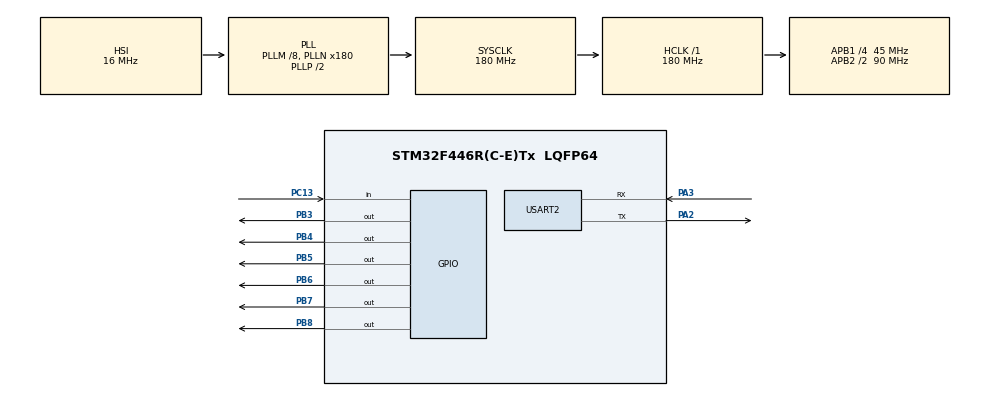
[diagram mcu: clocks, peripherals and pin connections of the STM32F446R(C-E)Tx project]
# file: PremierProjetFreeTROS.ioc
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FREERTOS.Tasks01=autoGreen,24,128,autoGreenStart,Default,NULL,Dynamic,NULL,NULL;autoYellow,24,128,autoYellowStart,Default,NULL,Dynamic,NULL,NULL;autoRed,24,128,autoRedStart,Default,NULL,Dynamic,NULL,NULL;pedGreen,24,128,pedGreenStart,Default,NULL,Dynamic,NULL,NULL;pedRed,24,128,pedRedStart,Default,NULL,Dynamic,NULL,NULL;buttonTask,40,128,buttonStart,Default,NULL,Dynamic,NULL,NULL
FREERTOS.configUSE_NEWLIB_REENTRANT=1
Mcu.Family=STM32F4
Mcu.Name=STM32F446R(C-E)Tx
Mcu.Package=LQFP64
NVIC.PriorityGroup=NVIC_PRIORITYGROUP_4
NVIC.TIM6_DAC_IRQn=true\:15\:0\:false\:false\:true\:false\:false\:true\:true
NVIC.TimeBase=TIM6_DAC_IRQn
NVIC.TimeBaseIP=TIM6
PA13.Mode=Serial_Wire
PA13.Signal=SYS_JTMS-SWDIO
PA14.Mode=Serial_Wire
PA14.Signal=SYS_JTCK-SWCLK
PA2.Mode=Asynchronous
PA2.Signal=USART2_TX
PA3.Mode=Asynchronous
PA3.Signal=USART2_RX
PB3.Signal=GPIO_Output
PB4.Signal=GPIO_Output
PB5.Signal=GPIO_Output
PB6.Signal=GPIO_Output
PB7.Signal=GPIO_Output
PB8.Signal=GPIO_Output
PC13.Signal=GPIO_Input
PH0-OSC_IN.Mode=HSE-External-Oscillator
PH0-OSC_IN.Signal=RCC_OSC_IN
PH1-OSC_OUT.Mode=HSE-External-Oscillator
PH1-OSC_OUT.Signal=RCC_OSC_OUT
ProjectManager.HeapSize=0x200
ProjectManager.StackSize=0x400
ProjectManager.TargetToolchain=STM32CubeIDE
RCC.48MHZClocksFreq_Value=84000000
RCC.AHBFreq_Value=180000000
RCC.APB1CLKDivider=RCC_HCLK_DIV4
RCC.APB1Freq_Value=45000000
RCC.APB1TimFreq_Value=90000000
RCC.APB2CLKDivider=RCC_HCLK_DIV2
RCC.APB2Freq_Value=90000000
RCC.APB2TimFreq_Value=180000000
RCC.CortexFreq_Value=180000000
RCC.FLatency-AdvancedSettings=FLASH_LATENCY_5
RCC.HCLKFreq_Value=180000000
RCC.HSE_VALUE=8000000
RCC.HSI_VALUE=16000000
RCC.PLLM=8
RCC.PLLN=180
RCC.SYSCLKFreq_VALUE=180000000
RCC.SYSCLKSource=RCC_SYSCLKSOURCE_PLLCLK
RCC.USBFreq_Value=180000000
RCC.VCOOutputFreq_Value=360000000
USART2.VirtualMode=VM_ASYNC
VP_FREERTOS_VS_CMSIS_V2.Mode=CMSIS_V2
VP_SYS_VS_tim6.Mode=TIM6
board=NUCLEO-F446RE

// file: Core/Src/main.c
/* USER CODE BEGIN Header */
/**
  ******************************************************************************
  * @file           : main.c
  * @brief          : Main program body
  ******************************************************************************
  * @attention
  *
  * Copyright (c) 2024 STMicroelectronics.
  * All rights reserved.
  *
  * This software is licensed under terms that can be found in the LICENSE file
  * in the root directory of this software component.
  * If no LICENSE file comes with this software, it is provided AS-IS.
  *
  ******************************************************************************
  */
/* USER CODE END Header */
#include "main.h"
#include "cmsis_os.h"

UART_HandleTypeDef huart2;

/* Definitions for autoRed */
osThreadId_t autoRedHandle;
const osThreadAttr_t autoRed_attributes = {
  .name = "autoRed",
  .stack_size = 128 * 4,
  .priority = (osPriority_t) osPriorityNormal,
};
/* Definitions for autoYellow */
osThreadId_t autoYellowHandle;
const osThreadAttr_t autoYellow_attributes = {
  .name = "autoYellow",
  .stack_size = 128 * 4,
  .priority = (osPriority_t) osPriorityNormal,
};
/* Definitions for autoGreen */
osThreadId_t autoGreenHandle;
const osThreadAttr_t autoGreen_attributes = {
  .name = "autoGreen",
  .stack_size = 128 * 4,
  .priority = (osPriority_t) osPriorityNormal,
};
/* Definitions for pedRed */
osThreadId_t pedRedHandle;
const osThreadAttr_t pedRed_attributes = {
  .name = "pedRed",
  .stack_size = 128 * 4,
  .priority = (osPriority_t) osPriorityNormal,
};
/* Definitions for pedGreen */
osThreadId_t pedGreenHandle;
const osThreadAttr_t pedGreen_attributes = {
  .name = "pedGreen",
  .stack_size = 128 * 4,
  .priority = (osPriority_t) osPriorityNormal,
};
/* Definitions for buttonTask */
osThreadId_t buttonTaskHandle;
const osThreadAttr_t buttonTask_attributes = {
  .name = "buttonTask",
  .stack_size = 128 * 4,
  .priority = (osPriority_t) osPriorityNormal,
};

void SystemClock_Config(void);
static void MX_GPIO_Init(void);
static void MX_USART2_UART_Init(void);
void autoRedStart(void *argument);
void autoYellowStart(void *argument);
void autoGreenStart(void *argument);
void pedRedStart(void *argument);
void pedGreenStart(void *argument);
void buttonStart(void *argument);

/* USER CODE BEGIN 0 */

int flag = 0;

/* USER CODE END 0 */

int main(void)
{

  /* MCU Configuration--------------------------------------------------------*/

  /* Reset of all peripherals, Initializes the Flash interface and the Systick. */
  HAL_Init();

  /* Configure the system clock */
  SystemClock_Config();

  /* Initialize all configured peripherals */
  MX_GPIO_Init();
  MX_USART2_UART_Init();

  /* Init scheduler */
  osKernelInitialize();

  /* Create the thread(s) */
  /* creation of autoRed */
  autoRedHandle = osThreadNew(autoRedStart, NULL, &autoRed_attributes);

  /* creation of autoYellow */
  autoYellowHandle = osThreadNew(autoYellowStart, NULL, &autoYellow_attributes);

  /* creation of autoGreen */
  autoGreenHandle = osThreadNew(autoGreenStart, NULL, &autoGreen_attributes);

  /* creation of pedRed */
  pedRedHandle = osThreadNew(pedRedStart, NULL, &pedRed_attributes);

  /* creation of pedGreen */
  pedGreenHandle = osThreadNew(pedGreenStart, NULL, &pedGreen_attributes);

  /* creation of buttonTask */
  buttonTaskHandle = osThreadNew(StartButtonTask, NULL, &buttonTask_attributes);

  /* Start scheduler */
  osKernelStart();

  /* We should never get here as control is now taken by the scheduler */
  /* Infinite loop */
  while (1)
  {

  }
}

void SystemClock_Config(void)
{
  RCC_OscInitTypeDef RCC_OscInitStruct = {0};
  RCC_ClkInitTypeDef RCC_ClkInitStruct = {0};

  /** Configure the main internal regulator output voltage
  */
  __HAL_RCC_PWR_CLK_ENABLE();
  __HAL_PWR_VOLTAGESCALING_CONFIG(PWR_REGULATOR_VOLTAGE_SCALE1);

  /** Initializes the RCC Oscillators according to the specified parameters
  * in the RCC_OscInitTypeDef structure.
  */
  RCC_OscInitStruct.OscillatorType = RCC_OSCILLATORTYPE_HSI;
  RCC_OscInitStruct.HSIState = RCC_HSI_ON;
  RCC_OscInitStruct.HSICalibrationValue = RCC_HSICALIBRATION_DEFAULT;
  RCC_OscInitStruct.PLL.PLLState = RCC_PLL_ON;
  RCC_OscInitStruct.PLL.PLLSource = RCC_PLLSOURCE_HSI;
  RCC_OscInitStruct.PLL.PLLM = 8;
  RCC_OscInitStruct.PLL.PLLN = 180;
  RCC_OscInitStruct.PLL.PLLP = RCC_PLLP_DIV2;
  RCC_OscInitStruct.PLL.PLLQ = 2;
  RCC_OscInitStruct.PLL.PLLR = 2;
  if (HAL_RCC_OscConfig(&RCC_OscInitStruct) != HAL_OK)
  {
    Error_Handler();
  }

  /** Activate the Over-Drive mode
  */
  if (HAL_PWREx_EnableOverDrive() != HAL_OK)
  {
    Error_Handler();
  }

  /** Initializes the CPU, AHB and APB buses clocks
  */
  RCC_ClkInitStruct.ClockType = RCC_CLOCKTYPE_HCLK|RCC_CLOCKTYPE_SYSCLK
                              |RCC_CLOCKTYPE_PCLK1|RCC_CLOCKTYPE_PCLK2;
  RCC_ClkInitStruct.SYSCLKSource = RCC_SYSCLKSOURCE_PLLCLK;
  RCC_ClkInitStruct.AHBCLKDivider = RCC_SYSCLK_DIV1;
  RCC_ClkInitStruct.APB1CLKDivider = RCC_HCLK_DIV4;
  RCC_ClkInitStruct.APB2CLKDivider = RCC_HCLK_DIV2;

  if (HAL_RCC_ClockConfig(&RCC_ClkInitStruct, FLASH_LATENCY_5) != HAL_OK)
  {
    Error_Handler();
  }
}

static void MX_USART2_UART_Init(void)
{

  huart2.Instance = USART2;
  huart2.Init.BaudRate = 115200;
  huart2.Init.WordLength = UART_WORDLENGTH_8B;
  huart2.Init.StopBits = UART_STOPBITS_1;
  huart2.Init.Parity = UART_PARITY_NONE;
  huart2.Init.Mode = UART_MODE_TX_RX;
  huart2.Init.HwFlowCtl = UART_HWCONTROL_NONE;
  huart2.Init.OverSampling = UART_OVERSAMPLING_16;
  if (HAL_UART_Init(&huart2) != HAL_OK)
  {
    Error_Handler();
  }

}

static void MX_GPIO_Init(void)
{
  GPIO_InitTypeDef GPIO_InitStruct = {0};

  /* GPIO Ports Clock Enable */
  __HAL_RCC_GPIOC_CLK_ENABLE();
  __HAL_RCC_GPIOH_CLK_ENABLE();
  __HAL_RCC_GPIOA_CLK_ENABLE();
  __HAL_RCC_GPIOB_CLK_ENABLE();

  /*Configure GPIO pin Output Level */
  HAL_GPIO_WritePin(GPIOB, GPIO_PIN_10|GPIO_PIN_3|GPIO_PIN_4|GPIO_PIN_5|GPIO_PIN_6, GPIO_PIN_RESET);

  /*Configure GPIO pin : PC13 */
  GPIO_InitStruct.Pin = GPIO_PIN_13;
  GPIO_InitStruct.Mode = GPIO_MODE_INPUT;
  GPIO_InitStruct.Pull = GPIO_NOPULL;
  HAL_GPIO_Init(GPIOC, &GPIO_InitStruct);

  /*Configure GPIO pins : PB10 PB3 PB4 PB5 */
  GPIO_InitStruct.Pin = GPIO_PIN_10|GPIO_PIN_3|GPIO_PIN_4|GPIO_PIN_5|GPIO_PIN_6;
  GPIO_InitStruct.Mode = GPIO_MODE_OUTPUT_PP;
  GPIO_InitStruct.Pull = GPIO_NOPULL;
  GPIO_InitStruct.Speed = GPIO_SPEED_FREQ_LOW;
  HAL_GPIO_Init(GPIOB, &GPIO_InitStruct);

}

void autoRedStart(void *argument) // auto red
{
  /* USER CODE BEGIN autoRedStart */
  /* Infinite loop */
  for(;;)
  {
    while(1){
	  	if( HAL_GPIO_ReadPin(GPIOC, GPIO_PIN_13) == 0 ){
	  	    break;
	  	}
	}
    osDelay(3000);
    HAL_GPIO_TogglePin(GPIOB,GPIO_PIN_3);
    osDelay(14000);
    HAL_GPIO_TogglePin(GPIOB,GPIO_PIN_3);

  }
  /* USER CODE END autoRedStart */
}

void autoYellowStart(void *argument) //auto orange
{
  /* USER CODE BEGIN StartAutoYellow */
  /* Infinite loop */
  for(;;)
  {

    while(1){
	  	if( HAL_GPIO_ReadPin(GPIOC, GPIO_PIN_13) == 0 ){
	  	    break;
	  	}
	}
    HAL_GPIO_TogglePin(GPIOB,GPIO_PIN_5);
    osDelay(3000);
    HAL_GPIO_TogglePin(GPIOB,GPIO_PIN_5);
    osDelay(12000);
    HAL_GPIO_TogglePin(GPIOB,GPIO_PIN_5);
    osDelay(2000);
    HAL_GPIO_TogglePin(GPIOB,GPIO_PIN_5);

  }
  /* USER CODE END autoYellowStart  */
}

void autoGreenStart(void *argument)  //Green Auto
{
  /* USER CODE BEGIN autoGreenStart */
  /* Infinite loop */
  for(;;)
  {

	HAL_GPIO_TogglePin(GPIOB,GPIO_PIN_4);
    while (1){
        if( HAL_GPIO_ReadPin(GPIOC, GPIO_PIN_13)==0){
            break;
        }
    }
    HAL_GPIO_TogglePin(GPIOB,GPIO_PIN_4);
    osDelay(17000);

  }
    /* USER CODE END autoGreenStart */
}

void pedRedStart(void *argument) //pedestrain red
{
  /* USER CODE BEGIN pedRedStart */
  /* Infinite loop */
  for(;;)
  {

    HAL_GPIO_TogglePin(GPIOB,GPO_PIN_10);
    while(1){
	  	if( HAL_GPIO_ReadPin(GPIOC, GPIO_PIN_13) == 0 ){
	  	    break;
	  	}
	}
    osDelay(4000);
    HAL_GPIO_TogglePin(GPIOB,GPO_PIN_10);
    osDelay(10000);

  }
  /* USER CODE END pedRedStart  */
}

/* USER CODE BEGIN Header_pedGreenStart */
/* USER CODE END Header_pedGreenStart  */
void pedGreenStart(void *argument) //pedestrain green
{
  /* USER CODE BEGIN pedGreenStart  */
  /* Infinite loop */
  for(;;)
  {
	while(1){
	  	if( HAL_GPIO_ReadPin(GPIOC, GPIO_PIN_13) == 0 ){
	  	    break;
	  	}
	}
    osDelay(4000);
    HAL_GPIO_TogglePin(GPIOB,GPO_PIN_6);
    osDelay(10000);
    HAL_GPIO_TogglePin(GPIOB,GPO_PIN_6);
  }
  /* USER CODE END pedGreenStart  */
}

void buttonStart(void *argument)
{
  /* USER CODE BEGIN buttonStart */
  /* Infinite loop */
  for(;;)
  {
	while(HAL_GPIO_ReadPin(GPIOC, GPIO_PIN_13)){
        uint8_t str2[] = "I got push-button\r\n";
        HAL_UART_Transmit(&huart2, str2, sizeof(str2), 10000);
        osDelay(17000);
    }

    }
     /* USER CODE END buttonStart */
}

void HAL_TIM_PeriodElapsedCallback(TIM_HandleTypeDef *htim)
{
  if (htim->Instance == TIM6) {
    HAL_IncTick();
  }
}

void Error_Handler(void)
{
  __disable_irq();
  while (1)
  {
  }
}
